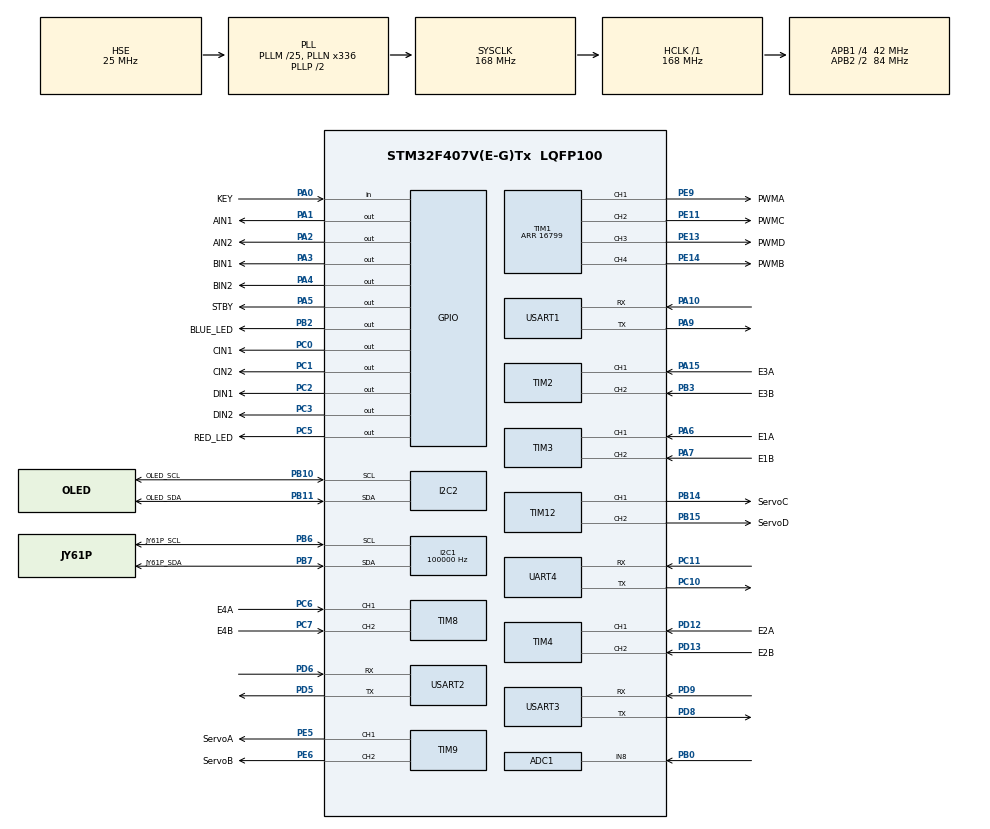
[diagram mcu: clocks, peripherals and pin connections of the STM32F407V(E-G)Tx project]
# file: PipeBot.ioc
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ADC1.Channel-20\#ChannelRegularConversion=ADC_CHANNEL_8
ADC1.NbrOfConversionFlag=1
ADC1.Rank-20\#ChannelRegularConversion=1
ADC1.SamplingTime-20\#ChannelRegularConversion=ADC_SAMPLETIME_112CYCLES
ADC1.master=1
Dma.Request0=USART1_RX
Dma.Request1=USART1_TX
Dma.Request2=USART3_RX
Dma.Request3=UART4_RX
Dma.Request4=USART2_RX
Dma.UART4_RX.3.Direction=DMA_PERIPH_TO_MEMORY
Dma.UART4_RX.3.FIFOMode=DMA_FIFOMODE_DISABLE
Dma.UART4_RX.3.Instance=DMA1_Stream2
Dma.UART4_RX.3.MemDataAlignment=DMA_MDATAALIGN_BYTE
Dma.UART4_RX.3.MemInc=DMA_MINC_ENABLE
Dma.UART4_RX.3.Mode=DMA_CIRCULAR
Dma.UART4_RX.3.PeriphDataAlignment=DMA_PDATAALIGN_BYTE
Dma.UART4_RX.3.PeriphInc=DMA_PINC_DISABLE
Dma.UART4_RX.3.Priority=DMA_PRIORITY_LOW
Dma.USART1_RX.0.Direction=DMA_PERIPH_TO_MEMORY
Dma.USART1_RX.0.FIFOMode=DMA_FIFOMODE_DISABLE
Dma.USART1_RX.0.Instance=DMA2_Stream2
Dma.USART1_RX.0.MemDataAlignment=DMA_MDATAALIGN_BYTE
Dma.USART1_RX.0.MemInc=DMA_MINC_ENABLE
Dma.USART1_RX.0.Mode=DMA_CIRCULAR
Dma.USART1_RX.0.PeriphDataAlignment=DMA_PDATAALIGN_BYTE
Dma.USART1_RX.0.PeriphInc=DMA_PINC_DISABLE
Dma.USART1_RX.0.Priority=DMA_PRIORITY_HIGH
Dma.USART1_TX.1.Direction=DMA_MEMORY_TO_PERIPH
Dma.USART1_TX.1.FIFOMode=DMA_FIFOMODE_DISABLE
Dma.USART1_TX.1.Instance=DMA2_Stream7
Dma.USART1_TX.1.MemDataAlignment=DMA_MDATAALIGN_BYTE
Dma.USART1_TX.1.MemInc=DMA_MINC_ENABLE
Dma.USART1_TX.1.Mode=DMA_NORMAL
Dma.USART1_TX.1.PeriphDataAlignment=DMA_PDATAALIGN_BYTE
Dma.USART1_TX.1.PeriphInc=DMA_PINC_DISABLE
Dma.USART1_TX.1.Priority=DMA_PRIORITY_HIGH
Dma.USART2_RX.4.Direction=DMA_PERIPH_TO_MEMORY
Dma.USART2_RX.4.FIFOMode=DMA_FIFOMODE_DISABLE
Dma.USART2_RX.4.Instance=DMA1_Stream5
Dma.USART2_RX.4.MemDataAlignment=DMA_MDATAALIGN_BYTE
Dma.USART2_RX.4.MemInc=DMA_MINC_ENABLE
Dma.USART2_RX.4.Mode=DMA_CIRCULAR
Dma.USART2_RX.4.PeriphDataAlignment=DMA_PDATAALIGN_BYTE
Dma.USART2_RX.4.PeriphInc=DMA_PINC_DISABLE
Dma.USART2_RX.4.Priority=DMA_PRIORITY_LOW
Dma.USART3_RX.2.Direction=DMA_PERIPH_TO_MEMORY
Dma.USART3_RX.2.FIFOMode=DMA_FIFOMODE_DISABLE
Dma.USART3_RX.2.Instance=DMA1_Stream1
Dma.USART3_RX.2.MemDataAlignment=DMA_MDATAALIGN_BYTE
Dma.USART3_RX.2.MemInc=DMA_MINC_ENABLE
Dma.USART3_RX.2.Mode=DMA_CIRCULAR
Dma.USART3_RX.2.PeriphDataAlignment=DMA_PDATAALIGN_BYTE
Dma.USART3_RX.2.PeriphInc=DMA_PINC_DISABLE
Dma.USART3_RX.2.Priority=DMA_PRIORITY_LOW
FREERTOS.BinarySemaphores01=Sem_TxComplete,Dynamic,NULL,Available;Sem_RxComplete,Dynamic,NULL,Available;Sem_I2C,Dynamic,NULL,Available;Sem_TOFLRxComplete,Dynamic,NULL,Available;Sem_TOFRRxComplete,Dynamic,NULL,Available
FREERTOS.Queues01=LEDQueue,16,LEDMessage*,0,Dynamic,NULL,NULL;UART_TxQueue,10,ProtocolFrame_t,0,Dynamic,NULL,NULL
FREERTOS.Tasks01=defaultTask,24,128,StartDefaultTask,Default,NULL,Dynamic,NULL,NULL;LEDTask,24,128,StartLEDTask,As external,NULL,Dynamic,NULL,NULL;KeyTask,40,128,StartKeyTask,As external,NULL,Dynamic,NULL,NULL;MotorTask,44,256,StartMotorTask,As external,NULL,Dynamic,NULL,NULL;SerialRxTask,32,256,StartSerialRxTask,As external,NULL,Dynamic,NULL,NULL;SerialTxTask,26,256,StartSerialTxTask,As external,NULL,Dynamic,NULL,NULL;IMUTask,34,256,StartIMUTask,As external,NULL,Dynamic,NULL,NULL;TOFTask,25,256,StartTOFTask,As external,NULL,Dynamic,NULL,NULL
I2C1.ClockSpeed=100000
I2C1.I2C_Mode=I2C_Fast
Mcu.Family=STM32F4
Mcu.Name=STM32F407V(E-G)Tx
Mcu.Package=LQFP100
NVIC.DMA1_Stream1_IRQn=true\:5\:0\:false\:false\:true\:true\:false\:true\:true
NVIC.DMA1_Stream2_IRQn=true\:5\:0\:false\:false\:true\:true\:false\:true\:true
NVIC.DMA1_Stream5_IRQn=true\:5\:0\:false\:false\:true\:true\:false\:true\:true
NVIC.DMA2_Stream2_IRQn=true\:6\:0\:true\:false\:true\:true\:false\:true\:true
NVIC.DMA2_Stream7_IRQn=true\:6\:0\:true\:false\:true\:true\:false\:true\:true
NVIC.I2C1_ER_IRQn=true\:5\:0\:false\:false\:true\:true\:true\:true\:true
NVIC.I2C1_EV_IRQn=true\:5\:0\:false\:false\:true\:true\:true\:true\:true
NVIC.PriorityGroup=NVIC_PRIORITYGROUP_4
NVIC.TIM6_DAC_IRQn=true\:15\:0\:false\:false\:true\:false\:false\:true\:true
NVIC.TimeBase=TIM6_DAC_IRQn
NVIC.TimeBaseIP=TIM6
NVIC.UART4_IRQn=true\:5\:0\:false\:false\:true\:true\:true\:true\:true
NVIC.USART1_IRQn=true\:5\:0\:true\:false\:true\:true\:true\:true\:true
NVIC.USART2_IRQn=true\:5\:0\:false\:false\:true\:true\:true\:true\:true
NVIC.USART3_IRQn=true\:5\:0\:false\:false\:true\:true\:true\:true\:true
PA0-WKUP.GPIO_Label=KEY
PA0-WKUP.GPIO_PuPd=GPIO_PULLDOWN
PA0-WKUP.Signal=GPIO_Input
PA1.GPIO_Label=AIN1
PA1.Signal=GPIO_Output
PA10.Mode=Asynchronous
PA10.Signal=USART1_RX
PA13.Mode=Serial_Wire
PA13.Signal=SYS_JTMS-SWDIO
PA14.Mode=Serial_Wire
PA14.Signal=SYS_JTCK-SWCLK
PA15.GPIO_Label=E3A
PA15.Signal=S_TIM2_CH1_ETR
PA2.GPIO_Label=AIN2
PA2.Signal=GPIO_Output
PA3.GPIO_Label=BIN1
PA3.Signal=GPIO_Output
PA4.GPIO_Label=BIN2
PA4.Signal=GPIO_Output
PA5.GPIO_Label=STBY
PA5.PinState=GPIO_PIN_SET
PA5.Signal=GPIO_Output
PA6.GPIO_Label=E1A
PA6.Signal=S_TIM3_CH1
PA7.GPIO_Label=E1B
PA7.Signal=S_TIM3_CH2
PA9.Mode=Asynchronous
PA9.Signal=USART1_TX
PB0.Signal=ADCx_IN8
PB10.GPIO_Label=OLED_SCL
PB10.GPIO_Pu=GPIO_PULLUP
PB10.Mode=I2C
PB10.Signal=I2C2_SCL
PB11.GPIO_Label=OLED_SDA
PB11.GPIO_Pu=GPIO_PULLUP
PB11.Mode=I2C
PB11.Signal=I2C2_SDA
PB14.GPIO_Label=ServoC
PB14.Signal=S_TIM12_CH1
PB15.GPIO_Label=ServoD
PB15.Signal=S_TIM12_CH2
PB2.GPIO_Label=BLUE_LED
PB2.PinState=GPIO_PIN_SET
PB2.Signal=GPIO_Output
PB3.GPIO_Label=E3B
PB3.Signal=S_TIM2_CH2
PB6.GPIO_Label=JY61P_SCL
PB6.GPIO_Pu=GPIO_PULLUP
PB6.Mode=I2C
PB6.Signal=I2C1_SCL
PB7.GPIO_Label=JY61P_SDA
PB7.GPIO_Pu=GPIO_PULLUP
PB7.Mode=I2C
PB7.Signal=I2C1_SDA
PC0.GPIO_Label=CIN1
PC0.Signal=GPIO_Output
PC1.GPIO_Label=CIN2
PC1.Signal=GPIO_Output
PC10.Mode=Asynchronous
PC10.Signal=UART4_TX
PC11.Mode=Asynchronous
PC11.Signal=UART4_RX
PC2.GPIO_Label=DIN1
PC2.Signal=GPIO_Output
PC3.GPIO_Label=DIN2
PC3.Signal=GPIO_Output
PC5.GPIO_Label=RED_LED
PC5.PinState=GPIO_PIN_SET
PC5.Signal=GPIO_Output
PC6.GPIO_Label=E4A
PC6.Signal=S_TIM8_CH1
PC7.GPIO_Label=E4B
PC7.Signal=S_TIM8_CH2
PD12.GPIO_Label=E2A
PD12.Signal=S_TIM4_CH1
PD13.GPIO_Label=E2B
PD13.Signal=S_TIM4_CH2
PD5.Mode=Asynchronous
PD5.Signal=USART2_TX
PD6.Mode=Asynchronous
PD6.Signal=USART2_RX
PD8.Mode=Asynchronous
PD8.Signal=USART3_TX
PD9.Mode=Asynchronous
PD9.Signal=USART3_RX
PE11.GPIO_Label=PWMC
PE11.Signal=S_TIM1_CH2
PE13.GPIO_Label=PWMD
PE13.Signal=S_TIM1_CH3
PE14.GPIO_Label=PWMB
PE14.Signal=S_TIM1_CH4
PE5.GPIO_Label=ServoA
PE5.Signal=S_TIM9_CH1
PE6.GPIO_Label=ServoB
PE6.Signal=S_TIM9_CH2
PE9.GPIO_Label=PWMA
PE9.Signal=S_TIM1_CH1
PH0-OSC_IN.Mode=HSE-External-Oscillator
PH0-OSC_IN.Signal=RCC_OSC_IN
PH1-OSC_OUT.Mode=HSE-External-Oscillator
PH1-OSC_OUT.Signal=RCC_OSC_OUT
ProjectManager.HeapSize=0x200
ProjectManager.StackSize=0x400
ProjectManager.TargetToolchain=CMake
RCC.48MHZClocksFreq_Value=84000000
RCC.AHBFreq_Value=168000000
RCC.APB1CLKDivider=RCC_HCLK_DIV4
RCC.APB1Freq_Value=42000000
RCC.APB1TimFreq_Value=84000000
RCC.APB2CLKDivider=RCC_HCLK_DIV2
RCC.APB2Freq_Value=84000000
RCC.APB2TimFreq_Value=168000000
RCC.CortexFreq_Value=168000000
RCC.HCLKFreq_Value=168000000
RCC.HSE_VALUE=25000000
RCC.HSI_VALUE=16000000
RCC.LSE_VALUE=32768
RCC.PLLM=25
RCC.PLLN=336
RCC.PLLSourceVirtual=RCC_PLLSOURCE_HSE
RCC.SYSCLKFreq_VALUE=168000000
RCC.SYSCLKSource=RCC_SYSCLKSOURCE_PLLCLK
RCC.VCOOutputFreq_Value=336000000
SH.ADCx_IN8.0=ADC1_IN8,IN8
SH.S_TIM12_CH1.0=TIM12_CH1,PWM Generation1 CH1
SH.S_TIM12_CH2.0=TIM12_CH2,PWM Generation2 CH2
SH.S_TIM1_CH1.0=TIM1_CH1,PWM Generation1 CH1
SH.S_TIM1_CH2.0=TIM1_CH2,PWM Generation2 CH2
SH.S_TIM1_CH3.0=TIM1_CH3,PWM Generation3 CH3
SH.S_TIM1_CH4.0=TIM1_CH4,PWM Generation4 CH4
SH.S_TIM2_CH1_ETR.0=TIM2_CH1,Encoder_Interface
SH.S_TIM2_CH2.0=TIM2_CH2,Encoder_Interface
SH.S_TIM3_CH1.0=TIM3_CH1,Encoder_Interface
SH.S_TIM3_CH2.0=TIM3_CH2,Encoder_Interface
SH.S_TIM4_CH1.0=TIM4_CH1,Encoder_Interface
SH.S_TIM4_CH2.0=TIM4_CH2,Encoder_Interface
SH.S_TIM8_CH1.0=TIM8_CH1,Encoder_Interface
SH.S_TIM8_CH2.0=TIM8_CH2,Encoder_Interface
SH.S_TIM9_CH1.0=TIM9_CH1,PWM Generation1 CH1
SH.S_TIM9_CH2.0=TIM9_CH2,PWM Generation2 CH2
TIM1.AutoReloadPreload=TIM_AUTORELOAD_PRELOAD_ENABLE
TIM1.Channel-PWM\ Generation1\ CH1=TIM_CHANNEL_1
TIM1.Channel-PWM\ Generation2\ CH2=TIM_CHANNEL_2
TIM1.Channel-PWM\ Generation3\ CH3=TIM_CHANNEL_3
TIM1.Channel-PWM\ Generation4\ CH4=TIM_CHANNEL_4
TIM1.Period=16799
TIM12.Channel-PWM\ Generation1\ CH1=TIM_CHANNEL_1
TIM12.Channel-PWM\ Generation2\ CH2=TIM_CHANNEL_2
TIM3.EncoderMode=TIM_ENCODERMODE_TI12
TIM4.EncoderMode=TIM_ENCODERMODE_TI12
TIM9.Channel-PWM\ Generation1\ CH1=TIM_CHANNEL_1
TIM9.Channel-PWM\ Generation2\ CH2=TIM_CHANNEL_2
UART4.VirtualMode=Asynchronous
USART1.VirtualMode=VM_ASYNC
USART2.VirtualMode=VM_ASYNC
USART3.VirtualMode=VM_ASYNC
VP_FREERTOS_VS_CMSIS_V2.Mode=CMSIS_V2
VP_SYS_VS_tim6.Mode=TIM6
VP_TIM1_VS_ClockSourceINT.Mode=Internal
board=custom

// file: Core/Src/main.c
/* USER CODE BEGIN Header */
/**
  ******************************************************************************
  * @file           : main.c
  * @brief          : Main program body
  ******************************************************************************
  * @attention
  *
  * Copyright (c) 2026 STMicroelectronics.
  * All rights reserved.
  *
  * This software is licensed under terms that can be found in the LICENSE file
  * in the root directory of this software component.
  * If no LICENSE file comes with this software, it is provided AS-IS.
  *
  ******************************************************************************
  */
/* USER CODE END Header */
#include "main.h"
#include "cmsis_os.h"
#include "adc.h"
#include "dma.h"
#include "i2c.h"
#include "tim.h"
#include "usart.h"
#include "gpio.h"

/* USER CODE BEGIN Includes */
#include "bsp_motor.h"
#include <stdio.h>
/* USER CODE END Includes */

void SystemClock_Config(void);
void MX_FREERTOS_Init(void);

/* USER CODE BEGIN 0 */
// 针对 GCC 编译器的重定向 (适用于 CLion / STM32CubeIDE)
int _write(int file, char *ptr, int len) {
  // 使用阻塞模式发送，确保数据完整打印
  // huart1 是你定义的串口句柄，根据实际情况修改（如 &huart2）
  HAL_UART_Transmit(&huart1, (uint8_t *)ptr, len, HAL_MAX_DELAY);
  return len;
}
/* USER CODE END 0 */

int main(void)
{

  /* MCU Configuration--------------------------------------------------------*/

  /* Reset of all peripherals, Initializes the Flash interface and the Systick. */
  HAL_Init();

  /* Configure the system clock */
  SystemClock_Config();

  /* Initialize all configured peripherals */
  MX_GPIO_Init();
  MX_DMA_Init();
  MX_USART1_UART_Init();
  MX_TIM1_Init();
  MX_TIM3_Init();
  MX_TIM4_Init();
  MX_I2C1_Init();
  MX_I2C2_Init();
  MX_ADC1_Init();
  MX_USART3_UART_Init();
  MX_UART4_Init();
  MX_USART2_UART_Init();
  MX_TIM2_Init();
  MX_TIM8_Init();
  MX_TIM9_Init();
  MX_TIM12_Init();
  /* USER CODE BEGIN 2 */
  MOTOR_PWM_START();
  MOTOR_ENCODER_START();

  /* USER CODE END 2 */

  /* Init scheduler */
  osKernelInitialize();  /* Call init function for freertos objects (in cmsis_os2.c) */
  MX_FREERTOS_Init();

  /* Start scheduler */
  osKernelStart();

  /* We should never get here as control is now taken by the scheduler */

  /* Infinite loop */
  while (1)
  {

  }
}

void SystemClock_Config(void)
{
  RCC_OscInitTypeDef RCC_OscInitStruct = {0};
  RCC_ClkInitTypeDef RCC_ClkInitStruct = {0};

  /** Configure the main internal regulator output voltage
  */
  __HAL_RCC_PWR_CLK_ENABLE();
  __HAL_PWR_VOLTAGESCALING_CONFIG(PWR_REGULATOR_VOLTAGE_SCALE1);

  /** Initializes the RCC Oscillators according to the specified parameters
  * in the RCC_OscInitTypeDef structure.
  */
  RCC_OscInitStruct.OscillatorType = RCC_OSCILLATORTYPE_HSE;
  RCC_OscInitStruct.HSEState = RCC_HSE_ON;
  RCC_OscInitStruct.PLL.PLLState = RCC_PLL_ON;
  RCC_OscInitStruct.PLL.PLLSource = RCC_PLLSOURCE_HSE;
  RCC_OscInitStruct.PLL.PLLM = 25;
  RCC_OscInitStruct.PLL.PLLN = 336;
  RCC_OscInitStruct.PLL.PLLP = RCC_PLLP_DIV2;
  RCC_OscInitStruct.PLL.PLLQ = 4;
  if (HAL_RCC_OscConfig(&RCC_OscInitStruct) != HAL_OK)
  {
    Error_Handler();
  }

  /** Initializes the CPU, AHB and APB buses clocks
  */
  RCC_ClkInitStruct.ClockType = RCC_CLOCKTYPE_HCLK|RCC_CLOCKTYPE_SYSCLK
                              |RCC_CLOCKTYPE_PCLK1|RCC_CLOCKTYPE_PCLK2;
  RCC_ClkInitStruct.SYSCLKSource = RCC_SYSCLKSOURCE_PLLCLK;
  RCC_ClkInitStruct.AHBCLKDivider = RCC_SYSCLK_DIV1;
  RCC_ClkInitStruct.APB1CLKDivider = RCC_HCLK_DIV4;
  RCC_ClkInitStruct.APB2CLKDivider = RCC_HCLK_DIV2;

  if (HAL_RCC_ClockConfig(&RCC_ClkInitStruct, FLASH_LATENCY_5) != HAL_OK)
  {
    Error_Handler();
  }
}

void HAL_TIM_PeriodElapsedCallback(TIM_HandleTypeDef *htim)
{
  if (htim->Instance == TIM6)
  {
    HAL_IncTick();
  }
}

void Error_Handler(void)
{
  __disable_irq();
  while (1)
  {
  }
}

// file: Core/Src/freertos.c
/* USER CODE BEGIN Header */
/**
  ******************************************************************************
  * File Name          : freertos.c
  * Description        : Code for freertos applications
  ******************************************************************************
  * @attention
  *
  * Copyright (c) 2026 STMicroelectronics.
  * All rights reserved.
  *
  * This software is licensed under terms that can be found in the LICENSE file
  * in the root directory of this software component.
  * If no LICENSE file comes with this software, it is provided AS-IS.
  *
  ******************************************************************************
  */
/* USER CODE END Header */

#include "FreeRTOS.h"
#include "task.h"
#include "main.h"
#include "cmsis_os.h"

/* USER CODE BEGIN Includes */
#include "Types/LEDType.h"
/* USER CODE END Includes */

/* Definitions for defaultTask */
osThreadId_t defaultTaskHandle;
const osThreadAttr_t defaultTask_attributes = {
  .name = "defaultTask",
  .stack_size = 128 * 4,
  .priority = (osPriority_t) osPriorityNormal,
};
/* Definitions for LEDTask */
osThreadId_t LEDTaskHandle;
const osThreadAttr_t LEDTask_attributes = {
  .name = "LEDTask",
  .stack_size = 128 * 4,
  .priority = (osPriority_t) osPriorityNormal,
};
/* Definitions for KeyTask */
osThreadId_t KeyTaskHandle;
const osThreadAttr_t KeyTask_attributes = {
  .name = "KeyTask",
  .stack_size = 128 * 4,
  .priority = (osPriority_t) osPriorityHigh,
};
/* Definitions for MotorTask */
osThreadId_t MotorTaskHandle;
const osThreadAttr_t MotorTask_attributes = {
  .name = "MotorTask",
  .stack_size = 256 * 4,
  .priority = (osPriority_t) osPriorityHigh4,
};
/* Definitions for SerialRxTask */
osThreadId_t SerialRxTaskHandle;
const osThreadAttr_t SerialRxTask_attributes = {
  .name = "SerialRxTask",
  .stack_size = 256 * 4,
  .priority = (osPriority_t) osPriorityAboveNormal,
};
/* Definitions for SerialTxTask */
osThreadId_t SerialTxTaskHandle;
const osThreadAttr_t SerialTxTask_attributes = {
  .name = "SerialTxTask",
  .stack_size = 256 * 4,
  .priority = (osPriority_t) osPriorityNormal2,
};
/* Definitions for IMUTask */
osThreadId_t IMUTaskHandle;
const osThreadAttr_t IMUTask_attributes = {
  .name = "IMUTask",
  .stack_size = 256 * 4,
  .priority = (osPriority_t) osPriorityAboveNormal2,
};
/* Definitions for TOFTask */
osThreadId_t TOFTaskHandle;
const osThreadAttr_t TOFTask_attributes = {
  .name = "TOFTask",
  .stack_size = 256 * 4,
  .priority = (osPriority_t) osPriorityNormal1,
};
/* Definitions for LEDQueue */
osMessageQueueId_t LEDQueueHandle;
const osMessageQueueAttr_t LEDQueue_attributes = {
  .name = "LEDQueue"
};
/* Definitions for UART_TxQueue */
osMessageQueueId_t UART_TxQueueHandle;
const osMessageQueueAttr_t UART_TxQueue_attributes = {
  .name = "UART_TxQueue"
};
/* Definitions for Sem_TxComplete */
osSemaphoreId_t Sem_TxCompleteHandle;
const osSemaphoreAttr_t Sem_TxComplete_attributes = {
  .name = "Sem_TxComplete"
};
/* Definitions for Sem_RxComplete */
osSemaphoreId_t Sem_RxCompleteHandle;
const osSemaphoreAttr_t Sem_RxComplete_attributes = {
  .name = "Sem_RxComplete"
};
/* Definitions for Sem_I2C */
osSemaphoreId_t Sem_I2CHandle;
const osSemaphoreAttr_t Sem_I2C_attributes = {
  .name = "Sem_I2C"
};
/* Definitions for Sem_TOFLRxComplete */
osSemaphoreId_t Sem_TOFLRxCompleteHandle;
const osSemaphoreAttr_t Sem_TOFLRxComplete_attributes = {
  .name = "Sem_TOFLRxComplete"
};
/* Definitions for Sem_TOFRRxComplete */
osSemaphoreId_t Sem_TOFRRxCompleteHandle;
const osSemaphoreAttr_t Sem_TOFRRxComplete_attributes = {
  .name = "Sem_TOFRRxComplete"
};

void StartDefaultTask(void *argument);
extern void StartLEDTask(void *argument);
extern void StartKeyTask(void *argument);
extern void StartMotorTask(void *argument);
extern void StartSerialRxTask(void *argument);
extern void StartSerialTxTask(void *argument);
extern void StartIMUTask(void *argument);
extern void StartTOFTask(void *argument);

void MX_FREERTOS_Init(void); /* (MISRA C 2004 rule 8.1) */

void MX_FREERTOS_Init(void) {

  /* Create the semaphores(s) */
  /* creation of Sem_TxComplete */
  Sem_TxCompleteHandle = osSemaphoreNew(1, 1, &Sem_TxComplete_attributes);

  /* creation of Sem_RxComplete */
  Sem_RxCompleteHandle = osSemaphoreNew(1, 1, &Sem_RxComplete_attributes);

  /* creation of Sem_I2C */
  Sem_I2CHandle = osSemaphoreNew(1, 1, &Sem_I2C_attributes);

  /* creation of Sem_TOFLRxComplete */
  Sem_TOFLRxCompleteHandle = osSemaphoreNew(1, 1, &Sem_TOFLRxComplete_attributes);

  /* creation of Sem_TOFRRxComplete */
  Sem_TOFRRxCompleteHandle = osSemaphoreNew(1, 1, &Sem_TOFRRxComplete_attributes);

  /* Create the queue(s) */
  /* creation of LEDQueue */
  LEDQueueHandle = osMessageQueueNew (16, sizeof(LEDMessage*), &LEDQueue_attributes);

  /* creation of UART_TxQueue */
  UART_TxQueueHandle = osMessageQueueNew (10, sizeof(ProtocolFrame_t), &UART_TxQueue_attributes);

  /* Create the thread(s) */
  /* creation of defaultTask */
  defaultTaskHandle = osThreadNew(StartDefaultTask, NULL, &defaultTask_attributes);

  /* creation of LEDTask */
  LEDTaskHandle = osThreadNew(StartLEDTask, NULL, &LEDTask_attributes);

  /* creation of KeyTask */
  KeyTaskHandle = osThreadNew(StartKeyTask, NULL, &KeyTask_attributes);

  /* creation of MotorTask */
  MotorTaskHandle = osThreadNew(StartMotorTask, NULL, &MotorTask_attributes);

  /* creation of SerialRxTask */
  SerialRxTaskHandle = osThreadNew(StartSerialRxTask, NULL, &SerialRxTask_attributes);

  /* creation of SerialTxTask */
  SerialTxTaskHandle = osThreadNew(StartSerialTxTask, NULL, &SerialTxTask_attributes);

  /* creation of IMUTask */
  IMUTaskHandle = osThreadNew(StartIMUTask, NULL, &IMUTask_attributes);

  /* creation of TOFTask */
  TOFTaskHandle = osThreadNew(StartTOFTask, NULL, &TOFTask_attributes);

}

void StartDefaultTask(void *argument)
{
  for(;;)
  {
    osDelay(1);
  }
}
